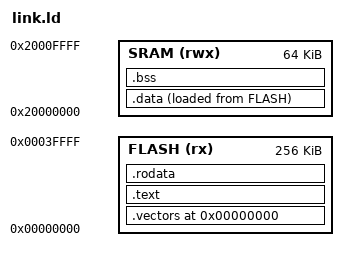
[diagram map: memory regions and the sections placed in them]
/* Linker script for lm3s6965evb (Cortex-M3) */
OUTPUT_ARCH(arm)
ENTRY(Reset_Handler)

MEMORY
{
    FLASH (rx)  : ORIGIN = 0x00000000, LENGTH = 256K
    SRAM  (rwx) : ORIGIN = 0x20000000, LENGTH = 64K
}

SECTIONS
{
    .vectors 0x00000000 : {
        KEEP(*(.vectors))
    } > FLASH

    .text : {
        *(.text.Reset_Handler)
        *(.text*)
    } > FLASH

    .rodata : {
        *(.rodata*)
    } > FLASH

    .data : {
        _sdata = .;
        *(.data*)
        _edata = .;
    } > SRAM AT > FLASH
    _sidata = LOADADDR(.data);

    .bss : {
        _sbss = .;
        *(.bss*)
        *(COMMON)
        _ebss = .;
    } > SRAM
}
